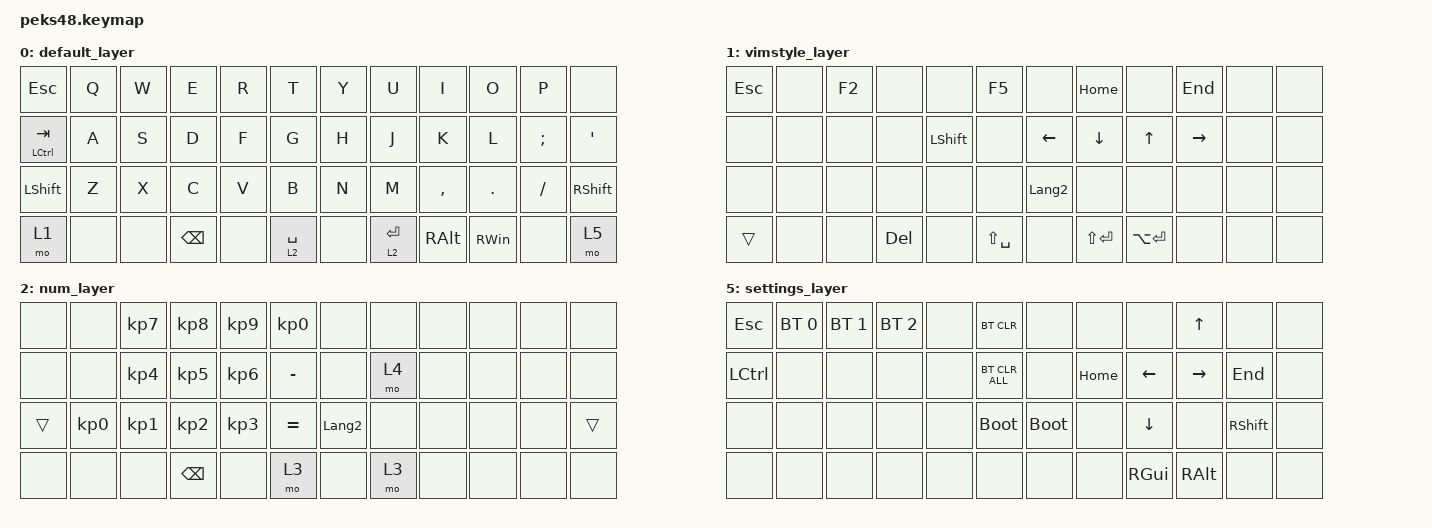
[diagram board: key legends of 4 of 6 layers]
#include <input/processors.dtsi>
#include <dt-bindings/zmk/input_transform.h>
#include <zephyr/dt-bindings/input/input-event-codes.h>
#include <behaviors.dtsi>
#include <dt-bindings/zmk/bt.h>
#include <dt-bindings/zmk/keys.h>
#include <dt-bindings/zmk/pointing.h>

// Conversion definition for using Japanese keyboard with OS settings

#define JP_DQUOTE       AT                // "
#define JP_AMPERSAND    CARET             // &
#define JP_QUOTE        AMPERSAND         // '
#define JP_EQUAL        UNDER             // =
#define JP_CARET        EQUAL             // ^
#define JP_YEN          0x89              // ¥
#define JP_PLUS         COLON             // +
#define JP_TILDE        PLUS              // ~
#define JP_PIPE         LS(0x89)          // |
#define JP_AT           LEFT_BRACKET      // @
#define JP_COLON        SINGLE_QUOTE      // :
#define JP_ASTERISK     DOUBLE_QUOTES     // *
#define JP_BACKQUOTE    LEFT_BRACE        // `
#define JP_UNDERSCORE   LS(0x87)          // _
#define JP_LBRACKET     RIGHT_BRACKET     // [
#define JP_RBRACKET     BACKSLASH         // ]
#define JP_LPAREN       ASTERISK          // (
#define JP_RPAREN       LEFT_PARENTHESIS  // )
#define JP_LBRACE       RIGHT_BRACE       // {
#define JP_RBRACE       PIPE              // }
#define JP_KANA         LANGUAGE_1        // かな
#define JP_EISU         LANGUAGE_2        // 英数
#define JP_HANZEN       GRAVE             // 半角/全角

/ {
    macros {
        double_zero: double_zero {
            compatible = "zmk,behavior-macro";
            #binding-cells = <0>;
            bindings = <&kp KP_NUMBER_0 &kp KP_NUMBER_0>;
            label = "DOUBLE_ZERO";
        };

        LR_parenthesises: LR_parenthesises {
            compatible = "zmk,behavior-macro";
            #binding-cells = <0>;
            bindings = <&kp LEFT_PARENTHESIS &kp RIGHT_PARENTHESIS>;
            label = "LR_parenthesises";
        };

        LR_brackets: LR_brackets {
            compatible = "zmk,behavior-macro";
            #binding-cells = <0>;
            bindings = <&kp LEFT_BRACKET &kp RIGHT_BRACKET>;
            label = "LR_brackets";
        };

        LR_braces: LR_braces {
            compatible = "zmk,behavior-macro";
            #binding-cells = <0>;
            bindings = <&kp LEFT_BRACE &kp RIGHT_BRACE>;
            label = "LR_braces";
        };
    };

    combos {
        compatible = "zmk,combos";

        m_RClick {
            bindings = <&mkp RCLK>;
            key-positions = <43 19>;
            layers = <0>;
        };
    };

    keymap {
        compatible = "zmk,keymap";

        default_layer {
            bindings = <
&kp ESCAPE      &kp Q  &kp W  &kp E          &kp R  &kp T          &kp Y  &kp U        &kp I          &kp O          &kp P          &none
&mt LCTRL TAB   &kp A  &kp S  &kp D          &kp F  &kp G          &kp H  &kp J        &kp K          &kp L          &kp SEMICOLON  &kp SQT
&kp LEFT_SHIFT  &kp Z  &kp X  &kp C          &kp V  &kp B          &kp N  &kp M        &kp COMMA      &kp DOT        &kp SLASH      &kp RIGHT_SHIFT
&mo 1           &none  &none  &kp BACKSPACE  &none  &lt 2 SPACE    &none  &lt 2 ENTER  &kp RIGHT_ALT  &kp RIGHT_WIN  &none          &mo 5
            >;
        };

        vimstyle_layer {
            bindings = <
&kp ESCAPE  &none  &kp F2  &none       &none           &kp F5           &none           &kp HOME       &none          &kp END    &none  &none
&none       &none  &none   &none       &kp LEFT_SHIFT  &none            &kp LEFT        &kp DOWN       &kp UP         &kp RIGHT  &none  &none
&none       &none  &none   &none       &none           &none            &kp LANGUAGE_2  &none          &none          &none      &none  &none
&trans      &none  &none   &kp DELETE  &none           &kp LS(SPACE)    &none           &kp LS(ENTER)  &kp LA(ENTER)  &none      &none  &none
            >;
        };

        num_layer {
            bindings = <
&none   &none            &kp KP_NUMBER_7  &kp KP_NUMBER_8  &kp KP_NUMBER_9  &kp KP_NUMBER_0    &none           &none  &none  &none  &none  &none
&none   &none            &kp KP_NUMBER_4  &kp KP_NUMBER_5  &kp KP_NUMBER_6  &kp MINUS          &none           &mo 4  &none  &none  &none  &none
&trans  &kp KP_NUMBER_0  &kp KP_NUMBER_1  &kp KP_NUMBER_2  &kp KP_NUMBER_3  &kp EQUAL          &kp LANGUAGE_2  &none  &none  &none  &none  &trans
&none   &none            &none            &kp BACKSPACE    &none            &mo 3              &none           &mo 3  &none  &none  &none  &none
            >;
        };

        symbol_layer {
            bindings = <
&kp GRAVE  &none  &kp AMPERSAND    &kp ASTERISK  &kp LEFT_PARENTHESIS  &kp RIGHT_PARENTHESIS    &none  &none  &none  &kp LEFT_PARENTHESIS  &kp RIGHT_PARENTHESIS  &kp BACKSLASH
&kp TILDE  &none  &kp DOLLAR       &kp PERCENT   &kp CARET             &kp RS(MINUS)            &none  &none  &none  &kp LEFT_BRACKET      &kp RIGHT_BRACKET      &kp PIPE
&none      &none  &kp EXCLAMATION  &kp AT_SIGN   &kp HASH              &kp RS(EQUAL)            &none  &none  &none  &kp LEFT_BRACE        &kp RIGHT_BRACE        &none
&none      &none  &none            &none
            >;
        };

        fn_layer {
            bindings = <
&none  &none  &kp F7  &kp F8  &kp F9  &kp F10    &none  &none  &none  &none  &none  &none
&none  &none  &kp F4  &kp F5  &kp F6  &kp F11    &none  &none  &none  &none  &none  &none
&none  &none  &kp F1  &kp F2  &kp F3  &kp F12    &none  &none  &none  &none  &none  &none
&none  &none  &none   &none
            >;
        };

        settings_layer {
            bindings = <
&kp ESCAPE        &bt BT_SEL 0  &bt BT_SEL 1  &bt BT_SEL 2  &none  &bt BT_CLR        &none        &none     &none           &kp UP_ARROW     &none            &none
&kp LEFT_CONTROL  &none         &none         &none         &none  &bt BT_CLR_ALL    &none        &kp HOME  &kp LEFT_ARROW  &kp RIGHT_ARROW  &kp END          &none
&none             &none         &none         &none         &none  &bootloader       &bootloader  &none     &kp DOWN_ARROW  &none            &kp RIGHT_SHIFT  &none
&none             &none         &none         &none         &none  &none             &none        &none     &kp RIGHT_GUI   &kp RIGHT_ALT    &none            &none
            >;
        };
    };
};
